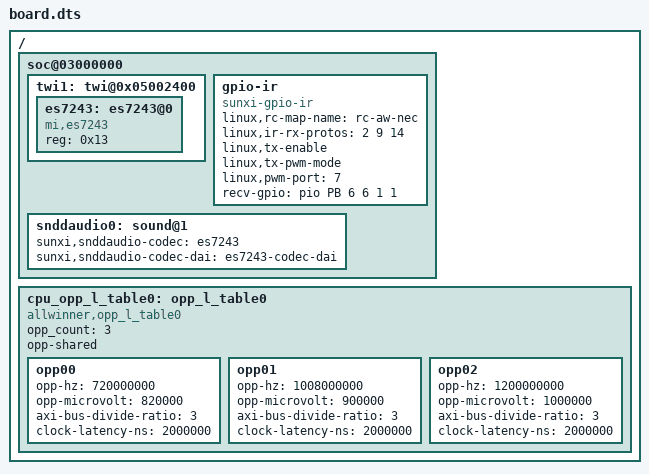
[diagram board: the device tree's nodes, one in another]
/*
 * Allwinner Technology CO., Ltd. sun8iw18p1 std board.
 *
 * soc board support.
 */

/dts-v1/;

#include "sun8iw18p1.dtsi"

/{
	soc@03000000 {
		twi1: twi@0x05002400 {
			status = "okay";
			es7243:es7243@0{
				compatible = "mi,es7243";
				reg = <0x13>;
				status = "okay";
			};
		};

		/*
		RC_TYPE_OTHER		= 1,
		RC_TYPE_RC5		= 2,
		RC_TYPE_RC5X		= 3,
		RC_TYPE_RC5_SZ		= 4,
		RC_TYPE_JVC		= 5,
		RC_TYPE_SONY12		= 6,
		RC_TYPE_SONY15		= 7,
		RC_TYPE_SONY20		= 8,
		RC_TYPE_NEC		= 9,
		RC_TYPE_NECX		= 10,
		RC_TYPE_NEC32		= 11,
		RC_TYPE_SANYO		= 12,
		RC_TYPE_MCE_KBD		= 13,
		RC_TYPE_RC6_0		= 14,
		RC_TYPE_RC6_6A_20	= 15,
		RC_TYPE_RC6_6A_24	= 16,
		RC_TYPE_RC6_6A_32	= 17,
		RC_TYPE_RC6_MCE		= 18,
		RC_TYPE_SHARP		= 19,
		RC_TYPE_XMP		= 20,
		RC_TYPE_CEC		= 21,
		*/

		gpio-ir{
			compatible = "sunxi-gpio-ir";
			linux,rc-map-name = "rc-aw-nec";
			linux,ir-rx-protos = <2 9 14>;
			linux,tx-enable;
			linux,tx-pwm-mode;
			linux,pwm-port = <7>;
			/*tran-gpio = <&pio PB 7 1 1 1 1>;*/
			recv-gpio = <&pio PB 6 6 1 1 1>;
			status = "okay";

		};

		/*
		gpio_ir_rx {
			compatible = "allwinner,gpio-ir-rx";
			gpio-rx = <&pio PB 0 6 1 1 1>;
			status = "okay";
		};

		gpio_ir_tx {
			compatible = "allwinner,gpio-ir-tx";
			gpio-tx = <&pio PB 1 1 1 1 1>;
			status = "okay";
		};
		*/

		snddaudio0:sound@1 {
			status = "okay";
			sunxi,snddaudio-codec = "es7243";
			sunxi,snddaudio-codec-dai = "es7243-codec-dai";
		};
	};


	cpu_opp_l_table0: opp_l_table0 {
		/* compatible = "operating-points-v2"; */
		compatible = "allwinner,opp_l_table0";
		opp_count = <3>;
		opp-shared;

		opp00 {
			opp-hz = /bits/ 64 <720000000>;
			opp-microvolt = <820000>;
			axi-bus-divide-ratio = <3>;
			clock-latency-ns = <2000000>;
		};

		opp01 {
			opp-hz = /bits/ 64 <1008000000>;
			opp-microvolt = <900000>;
			axi-bus-divide-ratio = <3>;
			clock-latency-ns = <2000000>;
		};

		opp02 {
			opp-hz = /bits/ 64 <1200000000>;
			opp-microvolt = <1000000>;
			axi-bus-divide-ratio = <3>;
			clock-latency-ns = <2000000>;
		};

		/*opp03 {
			opp-hz = /bits/ 64 <1512000000>;
			opp-microvolt = <1100000>;
			axi-bus-divide-ratio = <3>;
			clock-latency-ns = <2000000>;
		};*/

	};
	/*pwm config, use pwm to adapt volt; please cancel the comment
	 *polarity-> 0:NORMAL 1:INVERSED*/
	/*pwm_dvfs_info {
		period_ns = <50000>;
		polarity  = <0>;
		pwm_id    = <7>;
		vol_base  = <831000>;
		vol_max   = <1102000>;
	};*/

};
